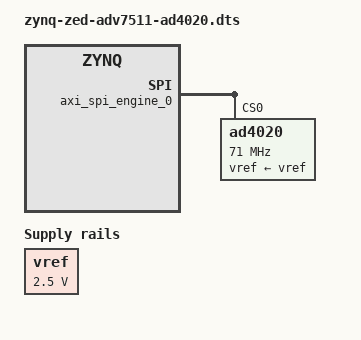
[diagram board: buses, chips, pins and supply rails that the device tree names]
// SPDX-License-Identifier: GPL-2.0
/*
 * Analog Devices AD4020
 * https://wiki.analog.com/resources/tools-software/linux-drivers/iio-adc/ad400x
 * https://wiki.analog.com/resources/eval/user-guides/ad400x
 *
 * hdl_project: <ad40xx_fmc/zed>
 * board_revision: <>
 *
 * Copyright (C) 2016-2019 Analog Devices Inc.
 */
/dts-v1/;

#include "zynq-zed.dtsi"
#include "zynq-zed-adv7511.dtsi"

/ {
	vref: regulator-vref {
		compatible = "regulator-fixed";
		regulator-name = "fixed-supply";
		regulator-min-microvolt = <2500000>;
		regulator-max-microvolt = <2500000>;
		regulator-always-on;
	};
};

&fpga_axi {
	rx_dma: rx-dmac@44a30000 {
		compatible = "adi,axi-dmac-1.00.a";
		reg = <0x44a30000 0x1000>;
		#dma-cells = <1>;
		interrupts = <0 57 IRQ_TYPE_LEVEL_HIGH>;
		clocks = <&clkc 16>;

		adi,channels {
			#size-cells = <0>;
			#address-cells = <1>;

			dma-channel@0 {
				reg = <0>;
				adi,source-bus-width = <32>;
				adi,source-bus-type = <1>;
				adi,destination-bus-width = <64>;
				adi,destination-bus-type = <0>;
			};
		};
	};

	axi_spi_engine_0: axi-spi-engine@44a00000 {
		compatible = "adi,axi-spi-engine-1.00.a";
		reg = <0x44a00000 0x1000>;
		interrupt-parent = <&intc>;
		interrupts = <0 56 IRQ_TYPE_LEVEL_HIGH>;
		clocks = <&clkc 15 &clkc 15>;
		clock-names = "s_axi_aclk", "spi_clk";
		num-cs = <1>;

		#address-cells = <0x1>;
		#size-cells = <0x0>;

		ad4020: adc@0 {
			compatible = "ad4020";
			reg = <0>;
			spi-max-frequency = <71000000>;

			dmas = <&rx_dma 0>;
			dma-names = "rx";

			vref-supply = <&vref>;
			#io-channel-cells = <1>;
		};
	};
};
